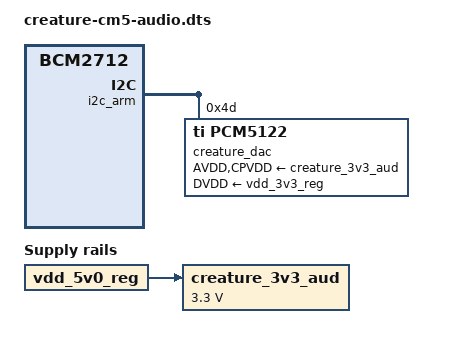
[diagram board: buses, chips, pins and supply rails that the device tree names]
// Analog line out on the Creature CM5 Carrier board (schematic sheet 7).
//
// PCM5122 DAC at 0x4D on I2C1, fed by RP1 I2S0 on GPIO18/19/21. The DAC's
// SCK pin is grounded, so there is no MCLK: the Pi drives BCLK and LRCLK
// and the pcm512x driver switches the DAC's PLL to run from BCLK.
//
// Uses only generic upstream drivers: simple-audio-card + pcm512x +
// designware-i2s. Replaces dtoverlay=allo-boss-dac-pcm512x-audio,slave;
// the two must not be enabled together (both claim the DAC at 0x4D).
/dts-v1/;
/plugin/;

/ {
	compatible = "brcm,bcm2712";

	// The DAC's supplies, so the codec driver needn't use dummies.
	// DVDD is the CM5's 3.3 V; AVDD/CPVDD come from the TLV75533 LDO
	// (AUD_U2), which runs from the 5 V rail.
	fragment@0 {
		target-path = "/";
		__overlay__ {
			creature_3v3_aud: regulator-creature-3v3-aud {
				compatible = "regulator-fixed";
				regulator-name = "3V3_AUD";
				regulator-min-microvolt = <3300000>;
				regulator-max-microvolt = <3300000>;
				vin-supply = <&vdd_5v0_reg>;
				regulator-always-on;
			};
		};
	};

	// RP1 I2S0, the instance that drives the bit and frame clocks.
	fragment@1 {
		target = <&i2s_clk_producer>;
		__overlay__ {
			status = "okay";
		};
	};

	fragment@2 {
		target = <&i2c_arm>;
		__overlay__ {
			#address-cells = <1>;
			#size-cells = <0>;
			status = "okay";

			creature_dac: dac@4d {
				compatible = "ti,pcm5122";
				reg = <0x4d>;
				#sound-dai-cells = <0>;
				AVDD-supply = <&creature_3v3_aud>;
				CPVDD-supply = <&creature_3v3_aud>;
				DVDD-supply = <&vdd_3v3_reg>;
			};
		};
	};

	fragment@3 {
		target-path = "/";
		__overlay__ {
			sound-creature-analog {
				compatible = "simple-audio-card";
				simple-audio-card,name = "Creature Analog Audio";
				simple-audio-card,format = "i2s";
				simple-audio-card,bitclock-master = <&creature_cpu>;
				simple-audio-card,frame-master = <&creature_cpu>;

				creature_cpu: simple-audio-card,cpu {
					sound-dai = <&i2s_clk_producer>;
				};
				simple-audio-card,codec {
					sound-dai = <&creature_dac>;
				};
			};
		};
	};
};
